AUTOSAR XML (schema 00046)
package /ComponentTypes
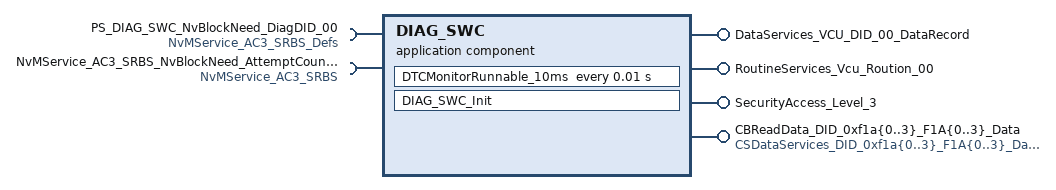
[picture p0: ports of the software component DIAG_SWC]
  application sw component type DIAG_SWC
    provide port DataServices_VCU_DID_00_DataRecord: provided-interface=DataServices_VCU_DID_00_DataRecord
      provided-com-specs:
        operation=ReadData, queue-length=1
        operation=ConditionCheckRead, queue-length=1
        operation=WriteData, queue-length=1
    require port PS_DIAG_SWC_NvBlockNeed_DiagDID_00: required-com-specs=[GetErrorStatus, SetRamBlockStatus, ReadBlock, WriteBlock, RestoreBlockDefaults, InvalidateNvBlock, EraseBlock], required-interface=NvMService_AC3_SRBS_Defs
    provide port RoutineServices_Vcu_Roution_00: provided-interface=RoutineServices_Vcu_Roution_00
      provided-com-specs:
        operation=Start, queue-length=1
        operation=Stop, queue-length=1
        operation=RequestResults, queue-length=1
    provide port SecurityAccess_Level_3: provided-interface=SecurityAccess_Level_3
      provided-com-specs:
        operation=GetSeed, queue-length=1
        operation=CompareKey, queue-length=1
        operation=GetSecurityAttemptCounter, queue-length=1
        operation=SetSecurityAttemptCounter, queue-length=1
    require port NvMService_AC3_SRBS_NvBlockNeed_AttemptCounter: required-com-specs=[WriteBlock, SetRamBlockStatus, ReadBlock, InvalidateNvBlock, GetErrorStatus, EraseBlock], required-interface=NvMService_AC3_SRBS
    4 x provide port, all with server-com-spec{operation=ReadData, queue-length=1}:
      CBReadData_DID_0xf1a{0..3}_F1A{0..3}_Data: provided-interface=CSDataServices_DID_0xf1a{0..3}_F1A{0..3}_Data
    behavior DIAG_SWC_InternalBehavior
      ar-typed-per-instance-memorys:
        data NvBlockNeed_DiagDID_00_MirrorBlock: sw-calibration-access=READ-ONLY, type=NvM_Arry4Bytes
        data NvBlockNeed_AttemptCounter_MirrorBlock: sw-calibration-access=READ-WRITE, type=uint8
      init event DIAG_SWC_InitEvent: start-on-event=DIAG_SWC_Init
      timing event TMT_DTCMonitorRunnable_10ms: start-on-event=DTCMonitorRunnable_10ms, period=0.01
      runnable DIAG_SWC_Init
      runnable DTCMonitorRunnable_10ms
      swc service dependency NvBlockNeed_DiagDID_00
        assigned-datas:
          role=ramBlock, used-data-element=NvBlockNeed_DiagDID_00_MirrorBlock
          role=defaultValue, used-parameter-element=NvBlockNeed_DiagDID_00_DefaultValue
        service-needs:
          nv block needs NvBlockNeed_DiagDID_00: calc-ram-block-crc=false, check-static-block-id=false, n-data-sets=0, ram-block-status-control=API, readonly=false, reliability=ERROR-DETECTION, resistant-to-changed-sw=true, restore-at-start=true, store-at-shutdown=true, store-cyclic=false, store-emergency=false, store-immediate=false, use-auto-validation-at-shut-down=false, use-crc-comp-mechanism=false, write-only-once=false, write-verification=false
      swc service dependency NvBlockNeed_AttemptCounter: assigned-ports=role-based-port-assignment={port-prototype=NvMService_AC3_SRBS_NvBlockNeed_AttemptCounter, role=NvMService_AC3_SRBS}
        assigned-datas:
          role=ramBlock, used-data-element=NvBlockNeed_AttemptCounter_MirrorBlock
          role=defaultValue, used-parameter-element=NvBlockNeed_AttemptCounter_DefaultValue
        service-needs:
          nv block needs NvBlockNeed_AttemptCounter: calc-ram-block-crc=false, check-static-block-id=false, n-data-sets=0, n-rom-blocks=1, ram-block-status-control=API, readonly=false, reliability=ERROR-DETECTION, resistant-to-changed-sw=true, restore-at-start=true, store-at-shutdown=true, store-cyclic=false, store-emergency=false, store-immediate=false, use-auto-validation-at-shut-down=false, use-crc-comp-mechanism=false, write-only-once=false, write-verification=false
      shared-parameters:
        parameter data prototype NvBlockNeed_DiagDID_00_DefaultValue: sw-calibration-access=READ-WRITE, type=NvM_Arry4Bytes, init-value=[0, 0, 0, 0]
        parameter data prototype NvBlockNeed_AttemptCounter_DefaultValue: sw-calibration-access=READ-WRITE, type=uint8, init-value=0
  swc implementation DIAG_SWC_Implementation: behavior=DIAG_SWC_InternalBehavior
